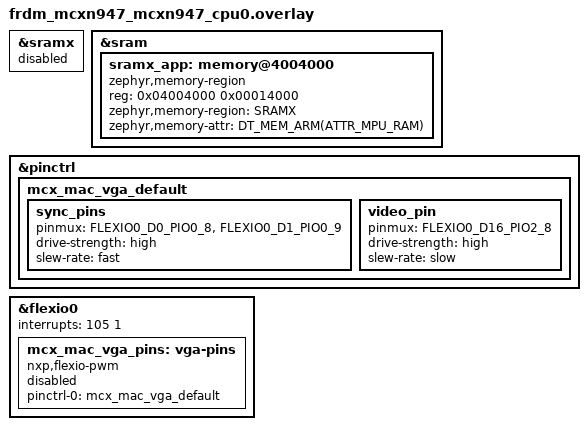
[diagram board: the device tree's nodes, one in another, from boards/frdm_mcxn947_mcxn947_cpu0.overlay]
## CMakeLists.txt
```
cmake_minimum_required(VERSION 3.20.0)

find_package(Zephyr REQUIRED HINTS $ENV{ZEPHYR_BASE})
project(mcx_mac)

# The public variant must neither link the legacy floppy driver nor embed
# private media. The post-build map/asset audit remains mandatory.
option(MCX_MAC_PUBLIC_RELEASE "Build an asset-free, release-audited image" ON)
if(MCX_MAC_PUBLIC_RELEASE AND
   (NOT CONFIG_MCX_MAC_UMAC_BOOT OR
    NOT CONFIG_MCX_MAC_UMAC_MEDIA_FROM_SLOT1 OR
    NOT CONFIG_MCX_MAC_INDEPENDENT_FLOPPY))
  message(FATAL_ERROR
    "Public uMac build requires boot + separate media slot + independent floppy. See RELEASE_STATUS.md")
endif()

if(MCX_MAC_PUBLIC_RELEASE AND CONFIG_MCX_MAC_USB_IMAGE_TRANSFER)
  message(FATAL_ERROR
    "Experimental USB transfer mode uses a test VID/PID and is not release-ready")
endif()

if(MCX_MAC_PUBLIC_RELEASE AND
   (CONFIG_MCX_MAC_UMAC_OPCODE_PROFILE OR CONFIG_MCX_MAC_UMAC_CYCLE_PROFILE))
  message(FATAL_ERROR "Diagnostic opcode profiling must not be included in a public build")
endif()

if(MCX_MAC_PUBLIC_RELEASE AND CONFIG_MCX_MAC_UMAC_MOVEM_MASK_ITER)
  message(FATAL_ERROR "Experimental MOVEM optimization is not release-validated")
endif()

if(MCX_MAC_PUBLIC_RELEASE AND CONFIG_MCX_MAC_UMAC_CPU_CONTEXT_RAMX)
  message(FATAL_ERROR "Experimental Musashi CPU context placement is not release-validated")
endif()

set(MCUX_CTIMER_DIR
  ${ZEPHYR_BASE}/../modules/hal/nxp/mcux/mcux-sdk-ng/drivers/ctimer)

target_include_directories(app PRIVATE
  src
  ${MCUX_CTIMER_DIR}
)

target_sources(app PRIVATE
  src/main.c
  src/emulator/m68k_bus.c
  src/emulator/m68k_bus_diag.c
  src/emulator/m68k_musashi_bus.c
  src/emulator/umac_memory.c
  src/emulator/umac_timing.c
  src/emulator/umac_video.c
  src/video/vga.c
  src/video/vga_flexio.c
  src/video/vga_smartdma.c
  src/video/vga_diag.c
  ${MCUX_CTIMER_DIR}/fsl_ctimer.c
)

if(CONFIG_MCX_MAC_EXTERNAL_FLASH_PROBE)
  target_sources(app PRIVATE src/emulator/umac_external_flash_probe.c)
endif()

if(CONFIG_MCX_MAC_EXTERNAL_FLASH_HDD)
  target_sources(app PRIVATE src/emulator/umac_flash_hdd.c)
endif()

if(CONFIG_MCX_MAC_EXTERNAL_FLASH_FAT_IMAGE)
  target_sources(app PRIVATE src/emulator/umac_fat_image.c)
endif()

if(CONFIG_MCX_MAC_USB_IMAGE_TRANSFER)
  target_sources(app PRIVATE src/usb/umac_usb_transfer.c)
endif()

if(CONFIG_MCX_MAC_SMARTDMA_DIRECT)
  if(CONFIG_MCX_MAC_SMARTDMA_GUEST_DESCRIPTOR)
    target_sources(app PRIVATE
      src/video/vga_smartdma_guest_ring.c
      src/video/vga_smartdma_guest_descriptors.c)
  else()
    target_sources(app PRIVATE src/video/vga_smartdma_ring.c)
  endif()
endif()

if(CONFIG_MCX_MAC_UMAC_CORE)
  if(NOT (CONFIG_MCX_MAC_UMAC_RAM_KIB EQUAL 128 OR
          CONFIG_MCX_MAC_UMAC_RAM_KIB EQUAL 192 OR
          CONFIG_MCX_MAC_UMAC_RAM_KIB EQUAL 208))
    message(FATAL_ERROR "Mac RAM must be 128, 192, or 208 KiB; the private ROM must match")
  endif()
  set(UMAC_DIR ${CMAKE_CURRENT_SOURCE_DIR}/external/umac)
  set(MUSASHI_DIR ${UMAC_DIR}/external/Musashi)
  set(UMAC_GEN_DIR ${CMAKE_CURRENT_BINARY_DIR}/umac_generated)
  set(UMAC_GENERATOR ${UMAC_GEN_DIR}/m68kmake)

  if(CONFIG_MCX_MAC_UMAC_RAM_KIB GREATER 192)
    # This board initializes only one EHCI host. Move the second instance's
    # untouched reserve, plus the CPU-only system heap, to free contiguous
    # main SRAM for the guest. Keep active USB DMA buffers in main SRAM.
    zephyr_code_relocate(
      FILES ${ZEPHYR_BASE}/../modules/hal/nxp/mcux/mcux-sdk-ng/middleware/usb/host/usb_host_ehci.c
      LOCATION SRAMX_BSS
      FILTER "^\\.bss\\.s_UsbHostEhci(FrameList2|Data2)$")
    zephyr_code_relocate(
      FILES ${ZEPHYR_BASE}/kernel/mempool.c
      LOCATION SRAMX_NOINIT
      FILTER "^\\.noinit\\..*kheap_buf__system_heap$")
  endif()

  if(NOT EXISTS ${MUSASHI_DIR}/m68kmake.c)
    message(FATAL_ERROR "uMac/Musashi not found; clone external/umac with --recursive")
  endif()

  find_program(UMAC_HOST_CC NAMES cc clang)
  if(NOT UMAC_HOST_CC)
    message(FATAL_ERROR "A host C compiler is required to generate Musashi opcodes")
  endif()

  set(UMAC_HOT_DECORATE_COMMAND)
  set(UMAC_HOT_DECORATE_DEPENDS)
  if(CONFIG_MCX_MAC_UMAC_HOT_OPS_RAM OR CONFIG_MCX_MAC_UMAC_HOT_OPS_RAMX)
    find_package(Python3 REQUIRED COMPONENTS Interpreter)
    set(UMAC_HOT_DECORATE_COMMAND
      COMMAND ${Python3_EXECUTABLE} ${UMAC_DIR}/tools/decorate_ops.py
              ${UMAC_GEN_DIR}/m68kops.c ${UMAC_DIR}/tools/fn_hot200.txt)
    set(UMAC_HOT_DECORATE_DEPENDS
      ${UMAC_DIR}/tools/decorate_ops.py ${UMAC_DIR}/tools/fn_hot200.txt)
  endif()

  set(UMAC_MOVEM_OPTIMIZE_COMMAND)
  set(UMAC_MOVEM_OPTIMIZE_DEPENDS)
  if(CONFIG_MCX_MAC_UMAC_MOVEM_MASK_ITER)
    find_package(Python3 REQUIRED COMPONENTS Interpreter)
    set(UMAC_MOVEM_OPTIMIZE_COMMAND
      COMMAND ${Python3_EXECUTABLE}
              ${CMAKE_CURRENT_SOURCE_DIR}/tools/optimize_m68kops_movem.py
              ${UMAC_GEN_DIR}/m68kops.c)
    set(UMAC_MOVEM_OPTIMIZE_DEPENDS
      ${CMAKE_CURRENT_SOURCE_DIR}/tools/optimize_m68kops_movem.py)
  endif()

  add_custom_command(
    OUTPUT ${UMAC_GEN_DIR}/m68kops.c ${UMAC_GEN_DIR}/m68kops.h
    COMMAND ${CMAKE_COMMAND} -E make_directory ${UMAC_GEN_DIR}
    COMMAND ${UMAC_HOST_CC} -O2 ${MUSASHI_DIR}/m68kmake.c -o ${UMAC_GENERATOR}
    COMMAND ${UMAC_GENERATOR} ${UMAC_GEN_DIR} ${MUSASHI_DIR}/m68k_in.c
    ${UMAC_HOT_DECORATE_COMMAND}
    ${UMAC_MOVEM_OPTIMIZE_COMMAND}
    DEPENDS ${MUSASHI_DIR}/m68kmake.c ${MUSASHI_DIR}/m68k_in.c
            ${UMAC_HOT_DECORATE_DEPENDS} ${UMAC_MOVEM_OPTIMIZE_DEPENDS}
    VERBATIM
  )

  target_include_directories(app PRIVATE
    ${UMAC_DIR}/include
    ${MUSASHI_DIR}
    ${UMAC_GEN_DIR}
  )
  target_compile_definitions(app PRIVATE
    UMAC_MEMSIZE=${CONFIG_MCX_MAC_UMAC_RAM_KIB}
    # Keep the original 30-step mouse backlog. Shorter 68000 slices let
    # the emulated mouse issue more quadrature steps per wall-clock second.
    MCX_MAC_GUEST_LOOP_MS=1
    MCX_MAC_MOUSE_SUBSTEPS=2
    MCX_MAC_USB_MOUSE_RATE_MAP=1
    DISP_WIDTH=512
    DISP_HEIGHT=342
    MUSASHI_CNF=\"${CMAKE_CURRENT_SOURCE_DIR}/src/emulator/mcx_m68kconf.h\"
  )
  set(UMAC_M68KCPU_SOURCE ${MUSASHI_DIR}/m68kcpu.c)
  if(CONFIG_MCX_MAC_UMAC_OPCODE_PROFILE OR CONFIG_MCX_MAC_UMAC_CYCLE_PROFILE)
    find_package(Python3 REQUIRED COMPONENTS Interpreter)
    set(UMAC_M68KCPU_SOURCE ${UMAC_GEN_DIR}/m68kcpu_profile.c)
    if(CONFIG_MCX_MAC_UMAC_CYCLE_PROFILE)
      set(UMAC_PROFILE_KIND cycles)
      target_sources(app PRIVATE src/emulator/mcx_cycle_profile.c)
    else()
      set(UMAC_PROFILE_KIND count)
      target_sources(app PRIVATE src/emulator/mcx_opcode_profile.c)
    endif()
    add_custom_command(
      OUTPUT ${UMAC_M68KCPU_SOURCE}
      COMMAND ${CMAKE_COMMAND} -E make_directory ${UMAC_GEN_DIR}
      COMMAND ${Python3_EXECUTABLE}
              ${CMAKE_CURRENT_SOURCE_DIR}/tools/instrument_m68kcpu.py
              ${MUSASHI_DIR}/m68kcpu.c ${UMAC_M68KCPU_SOURCE}
              ${UMAC_PROFILE_KIND}
      DEPENDS ${MUSASHI_DIR}/m68kcpu.c
              ${CMAKE_CURRENT_SOURCE_DIR}/tools/instrument_m68kcpu.py
      VERBATIM
    )
  endif()
  if(CONFIG_MCX_MAC_UMAC_CPU_CONTEXT_RAMX)
    find_package(Python3 REQUIRED COMPONENTS Interpreter)
    set(UMAC_M68KCPU_CONTEXT_INPUT ${UMAC_M68KCPU_SOURCE})
    set(UMAC_M68KCPU_SOURCE ${UMAC_GEN_DIR}/m68kcpu_context_ramx.c)
    add_custom_command(
      OUTPUT ${UMAC_M68KCPU_SOURCE}
      COMMAND ${Python3_EXECUTABLE}
              ${CMAKE_CURRENT_SOURCE_DIR}/tools/place_m68kcpu_context_ramx.py
              ${UMAC_M68KCPU_CONTEXT_INPUT} ${UMAC_M68KCPU_SOURCE}
      DEPENDS ${UMAC_M68KCPU_CONTEXT_INPUT}
              ${CMAKE_CURRENT_SOURCE_DIR}/tools/place_m68kcpu_context_ramx.py
      VERBATIM
    )
  endif()
  target_sources(app PRIVATE
    src/emulator/umac_block_backend.c
    src/emulator/umac_media_package.c
    ${UMAC_DIR}/src/main.c
    ${UMAC_DIR}/src/via.c
    ${UMAC_DIR}/src/scc.c
    ${UMAC_DIR}/src/rtc.c
    ${UMAC_M68KCPU_SOURCE}
    ${MUSASHI_DIR}/m68kdasm.c
    ${UMAC_GEN_DIR}/m68kops.c
  )
  if(CONFIG_MCX_MAC_UMAC_HOT_OPS_RAMX)
    zephyr_code_relocate(
      FILES ${MUSASHI_DIR}/m68kcpu.c ${UMAC_GEN_DIR}/m68kops.c
      LOCATION SRAMXHOT
      FILTER "^\\.text\\.mcx_hot$")
  endif()
  if(CONFIG_MCX_MAC_UMAC_CPU_O2)
    set_source_files_properties(
      ${UMAC_M68KCPU_SOURCE}
      ${UMAC_GEN_DIR}/m68kops.c
      PROPERTIES COMPILE_OPTIONS "-O2")
  endif()
  target_sources(app PRIVATE src/emulator/umac_floppy.c)
  if(CONFIG_MCX_MAC_UMAC_SMOKE)
    target_sources(app PRIVATE src/emulator/umac_smoke.c)
  endif()
  if(CONFIG_MCX_MAC_UMAC_BOOT)
    target_sources(app PRIVATE
      src/emulator/umac_disk_overlay.c
      src/emulator/umac_serial_input.c)
    target_sources(app PRIVATE src/emulator/umac_media_slot_boot.c)
    if(CONFIG_MCX_MAC_USB_MOUSE)
      target_sources(app PRIVATE src/emulator/umac_usb_hid.c)
      target_include_directories(app PRIVATE ${ZEPHYR_BASE}/subsys/usb/host)
    endif()
  endif()
endif()
```

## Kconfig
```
mainmenu "mcx_mac"

source "Kconfig.zephyr"

config MCX_MAC_FLEXIO
	bool
	default y
	select MCUX_FLEXIO
	help
	  Build the MCX-N FlexIO timing backend. The application attaches its
	  timer resource to Zephyr's shared NXP FlexIO controller.

config MCX_MAC_EDMA_LINKED
	bool "Use experimental eDMA TCD line linking"
	default n
	depends on MCX_MAC_FLEXIO
	help
	  Use MCUXpresso eDMA TCDs linked at each 512-pixel line boundary.
	  The linked diagnostic path is disabled by default until hardware
	  measurements confirm its FlexIO request gating.

config MCX_MAC_SOLID_VIDEO_DIAG
	bool "Drive a solid VIDEO rectangle without DMA"
	default n
	depends on MCX_MAC_FLEXIO
	help
	  Diagnostic mode which bypasses eDMA and the pixel serializer. The
	  HSYNC line interrupt drives a solid green rectangle directly, allowing
	  the analog/sync path to be separated from packed framebuffer scanout.

config MCX_MAC_HARDWARE_VIDEO_DIAG
	bool "Generate a periodic VIDEO window entirely in FlexIO"
	default n
	depends on MCX_MAC_FLEXIO
	help
	  Diagnostic mode which bypasses eDMA, the pixel serializer, and the
	  per-scanline CPU interrupt. A second FlexIO timer produces the VIDEO
	  window from the same clock as HSYNC so line-to-line timing cannot jitter.

config MCX_MAC_CONTINUOUS_RASTER
	bool "Stream a complete VGA raster without per-line CPU starts"
	default n
	depends on MCX_MAC_FLEXIO
	help
	  Expand the monochrome framebuffer into a packed 800 by 525 raster and
	  stream it continuously with one cyclic eDMA TCD. HSYNC and pixels share
	  the FlexIO clock and no scanline interrupt participates in video timing.

config MCX_MAC_SMARTDMA_DIRECT
	bool "Experimental SmartDMA one-frame FlexIO scanout"
	default n
	depends on MCX_MAC_CONTINUOUS_RASTER
	help
	  Replace the two-frame eDMA raster with a single 800x525 frame streamed
	  by a custom SmartDMA program. This is an experimental video path; leave
	  disabled in the known-working public build until display verification.

config MCX_MAC_SMARTDMA_RAW_PIXEL_ALIAS
	bool "Experimental raw raster through FlexIO bit-byte-swap alias"
	default n
	depends on MCX_MAC_SMARTDMA_DIRECT
	help
	  Keep the existing full-frame SmartDMA source but store raw Macintosh
	  pixel bytes in it. Direct SmartDMA writes to FlexIO SHIFTBUFBBS reverse
	  each byte's bits in hardware. This isolates alias behavior before a
	  direct guest-memory reader replaces the full-frame raster.

config MCX_MAC_SMARTDMA_GUEST_DESCRIPTOR
	bool "Experimental direct guest-framebuffer SmartDMA scanout"
	default n
	depends on MCX_MAC_SMARTDMA_DIRECT && MCX_MAC_SMARTDMA_RAW_PIXEL_ALIAS
	depends on !MCX_MAC_VIDEO_RAM_BANK
	help
	  Store the VGA scan schedule in Flash and have SmartDMA fetch packed
	  pixels directly from the Macintosh framebuffer. This removes the
	  52,500-byte expanded raster but is still an experimental video path.

config MCX_MAC_VIDEO_RAM_BANK
	bool "Place the SmartDMA raster wholly in the final 64 KiB main-RAM bank"
	default n
	depends on MCX_MAC_SMARTDMA_DIRECT
	help
	  Requires boards/smartdma_video_bank.overlay. The overlay shrinks the
	  normal application RAM to 256 KiB and reserves the final 64 KiB bank
	  for the 52,500-byte raster so SmartDMA reads cannot cross a RAM bank.

config MCX_MAC_FRAMEBUFFER_SRAMX
	bool "Place the CPU-side Macintosh framebuffer in SRAMX"
	default n
	depends on MCX_MAC_CONTINUOUS_RASTER
	help
	  Experimental RAM-placement option. Move the 512x342 monochrome
	  conversion framebuffer (21,888 bytes) from the nearly full main RAM
	  into SRAMX. Continuous eDMA still reads its existing two-frame raster
	  from main RAM; timing and transfer descriptors do not change.

config MCX_MAC_ANIMATED_TEST
	bool "Animate the checkerboard through vertical-blank commits"
	default n
	depends on MCX_MAC_CONTINUOUS_RASTER
	help
	  Shift the checkerboard by eight pixels twice per second. This verifies
	  that framebuffer changes can be committed during vertical blank while
	  the cyclic scanout DMA remains uninterrupted.

config MCX_MAC_M68K_BUS_DIAG
	bool "Run the 68000 memory-bus and CPU-callback self-test"
	default y
	help
	  Verify the 24-bit address mask, big-endian accesses, reset ROM overlay,
	  RAM writes below the overlay, unmapped-access diagnostics, and the
	  Musashi-compatible memory callback adapter. No CPU core runs yet.

config MCX_MAC_UMAC_CORE
	bool "Compile the upstream uMac/Musashi 128K core"
	default n
	help
	  Compile the upstream emulator from external/umac with generated
	  Musashi opcode sources. This option alone does not run guest code;
	  a user-provided, patched ROM and disc image are still required.

config MCX_MAC_EXTERNAL_FLASH_PROBE
	bool "Read-only probe of onboard FlexSPI NOR for future disk backend"
	default n
	depends on FLASH
	help
	  Check the onboard external NOR device, JEDEC ID, capacity, and whether
	  its first and last erase sectors are blank. This option never erases or
	  writes external Flash and does not change the guest disk backend.

config MCX_MAC_EXTERNAL_FLASH_WRITE_TEST
	bool "Test and restore one confirmed-blank external Flash sector"
	default n
	depends on MCX_MAC_EXTERNAL_FLASH_PROBE
	help
	  On a matching W25Q64 only, require the final 4 KiB sector to be all
	  0xff, program a 256-byte pattern, verify it, erase the sector, and
	  verify it is blank again. Never run on a nonblank sector. This is an
	  opt-in development test; it does not enable persistent guest writes.

config MCX_MAC_UMAC_FIXED_DISK_ROM
	bool "Use the experimental two-drive private Macintosh ROM"
	default n
	help
	  Require the private ROM variant with a second, fixed-disk Device
	  Manager entry. This does not require or access external Flash by
	  itself and is useful for isolating Macintosh boot behavior.

config MCX_MAC_EXTERNAL_FLASH_HDD
	bool "Build external Flash Macintosh fixed-disk backend (experimental)"
	default n
	depends on FLASH
	select MCX_MAC_UMAC_FIXED_DISK_ROM
	help
	  Build the fixed-disk block backend in the onboard W25Q64. The first
	  and last 64 KiB erase sectors are reserved, with one additional 4 KiB
	  header, yielding a 16120-sector device as Mac drive 8. It never
	  automatically initializes blank Flash. The
	  Mac can then initialize it as a normal volume. Writes currently use
	  non-atomic erase-block read/modify/write and are not power-loss safe.

config MCX_MAC_EXTERNAL_FLASH_FAT_IMAGE
	bool "Use an existing raw HFS/MFS image file on the external FAT volume"
	default n
	depends on FLASH && DISK_DRIVER_FLASH && FAT_FILESYSTEM_ELM
	depends on !MCX_MAC_EXTERNAL_FLASH_HDD
	select MCX_MAC_UMAC_FIXED_DISK_ROM
	help
	  Open /NAND:/umac0.img as Mac drive 8. HFS is writable; MFS is
	  read-only pending fixed-disk compatibility testing. The volume and file
	  must already exist; firmware does not format the volume or create/truncate
	  the image.
	  Do not expose the FAT volume to a USB host while the Mac is using it.

config MCX_MAC_USB_IMAGE_TRANSFER
	bool "Experimental SW2-selected USB image transfer mode"
	default n
	depends on MCX_MAC_EXTERNAL_FLASH_FAT_IMAGE && USB_DEVICE_STACK_NEXT
	depends on USBD_MSC_CLASS && USB_HOST_STACK && GPIO
	help
	  Compile both USB1 roles. Holding user SW2 at startup starts the USB
	  device/MSC mode instead of the Macintosh. This is a private build probe
	  with a non-production VID/PID, not a release feature.

config MCX_MAC_EXTERNAL_FLASH_HDD_FORMAT_BLANK
	bool "Explicitly initialize a completely blank external Flash HDD area"
	default n
	depends on MCX_MAC_EXTERNAL_FLASH_HDD
	help
	  Development-only, one-time operation. Formatting scans the disk area and
	  refuses to modify it if any byte is not erased. This does not create an
	  HFS volume. Never enable in a normal release image.

config MCX_MAC_EXTERNAL_FLASH_HDD_SKIP_MEDIA
	bool "Keep fixed-disk ROM driver but do not access external media"
	default n
	depends on MCX_MAC_EXTERNAL_FLASH_HDD
	depends on !MCX_MAC_EXTERNAL_FLASH_HDD_FORMAT_BLANK
	help
	  Diagnostic only: boot with the two-drive ROM patch but leave drive 8
	  unattached. This isolates guest driver registration from external NOR
	  reads and writes. The System floppy remains available.

config MCX_MAC_UMAC_SMOKE
	bool "Run a synthetic uMac/Musashi CPU smoke test"
	default n
	depends on MCX_MAC_UMAC_CORE
	help
	  Execute a short 68000 branch loop from a project-owned synthetic ROM.
	  This is only a CPU/link test, not Macintosh boot or video output.

config MCX_MAC_UMAC_BOOT
	bool "Boot uMac with locally supplied ROM and disk"
	default n
	depends on MCX_MAC_UMAC_CORE && MCX_MAC_CONTINUOUS_RASTER
	help
	  Embed user-supplied ROM and disk images into a local firmware build.
	  Neither image is copied into the source tree. Do not distribute the
	  resulting firmware without appropriate rights to those images.

config MCX_MAC_UMAC_PERF_DIAG
	bool "Measure uMac loop and video-service CPU time"
	default n
	depends on MCX_MAC_UMAC_BOOT
	help
	  Record cycle counts for the guest loop, video copy, raster service and
	  main-thread sleep. Print aggregate timing every five seconds. Keep this
	  disabled in the normal build to avoid adding timing probes to hot paths.

config MCX_MAC_UMAC_INSTR_COUNT
	bool "Count executed guest 68000 instructions for a diagnostic build"
	default n
	depends on MCX_MAC_UMAC_BOOT
	help
	  Increment a counter for each 68000 instruction and report kIPS every
	  five seconds. The hook adds overhead, so compare two builds made with
	  this same option rather than treating its rate as an uninstrumented MIPS.

config MCX_MAC_UMAC_RAM_KIB
	int "Macintosh guest RAM in KiB"
	default 128
	range 128 208
	depends on MCX_MAC_UMAC_CORE
	help
	  The 128 KiB normal build is unchanged. Larger values need the matching
	  private ROM memory-top patch, and enough contiguous CPU0 RAM. The
	  192 KiB variant moves the CPU-side framebuffer into SRAMX. The 208 KiB
	  variant also moves unused USB reserve data and the system heap to SRAMX.
	  Only 128, 192, and 208 KiB have matching private ROM patches.

config MCX_MAC_UMAC_OPCODE_PROFILE
	bool "Sample executed Musashi opcode handlers for a diagnostic build"
	default n
	depends on MCX_MAC_UMAC_BOOT && !MCX_MAC_UMAC_HOT_OPS_RAM && !MCX_MAC_UMAC_HOT_OPS_RAMX
	help
	  Sample the actual opcode-handler dispatch on CPU0, storing counts in
	  spare RAMX. The generated Musashi source is instrumented only for this
	  diagnostic build; the vendored submodule and release image are untouched.

config MCX_MAC_UMAC_CYCLE_PROFILE
	bool "Sample actual CPU cycles spent in Musashi opcode handlers"
	default n
	depends on MCX_MAC_UMAC_BOOT && !MCX_MAC_UMAC_HOT_OPS_RAM && !MCX_MAC_UMAC_HOT_OPS_RAMX && !MCX_MAC_UMAC_OPCODE_PROFILE
	help
	  Time one of approximately every 64 dispatched guest instructions and
	  rank handlers by accumulated CPU cycles, not just execution frequency.
	  This diagnostic has measurement overhead and may include interrupt time.
	  The sample table occupies 16 KiB of main RAM; do not enable in release.

config MCX_MAC_UMAC_MOVEM_MASK_ITER
	bool "Experiment with set-bit iteration in two hot MOVEM handlers"
	default n
	depends on MCX_MAC_UMAC_BOOT && !MCX_MAC_UMAC_HOT_OPS_RAM && !MCX_MAC_UMAC_HOT_OPS_RAMX
	help
	  Rewrite only the generated copies of MOVEM.L register-to-memory
	  predecrement and memory-to-register postincrement handlers. Iterate
	  selected register bits instead of testing all 16 slots. This is an
	  experimental A/B optimization; leave disabled in a release build.

config MCX_MAC_UMAC_CPU_CONTEXT_RAMX
	bool "Experiment with Musashi CPU register state in app SRAMX"
	default n
	depends on MCX_MAC_UMAC_BOOT && !MCX_MAC_UMAC_HOT_OPS_RAMX
	help
	  Relocate only the 536-byte Musashi CPU state to the existing app SRAMX
	  data bank. The guest RAM, opcode dispatch table and firmware stay in
	  their original locations. This is an experimental A/B option.

config MCX_MAC_UMAC_HOT_OPS_RAM
	bool "Experiment with uMac's hot 200 opcode handlers in RAM"
	default n
	depends on MCX_MAC_UMAC_BOOT && ARCH_HAS_RAMFUNC_SUPPORT
	help
	  Decorate uMac's profiled 200 opcode handlers and the Musashi dispatcher
	  for Zephyr's startup-copied executable .ramfunc section. This first
	  experiment uses ordinary CPU0 RAM, not RAMX, because the existing RAMX
	  device-tree region is data-only under the MPU. Leave off in release
	  builds until speed, free RAM and video stability are measured.

config MCX_MAC_UMAC_HOT_OPS_RAMX
	bool "Experiment with uMac's hot 200 opcode handlers in isolated RAMX"
	default n
	depends on MCX_MAC_UMAC_BOOT && CODE_DATA_RELOCATION && !MCX_MAC_UMAC_HOT_OPS_RAM
	help
	  Relocate the 200 profiled handlers and the Musashi dispatcher to a
	  dedicated executable RAMX bank. The disk overlay remains in a separate
	  32 KiB RAMX region. This is an experimental diagnostic build only.

config MCX_MAC_USB_THREAD_PROFILE
	bool "Measure USB host thread CPU time"
	default n
	depends on MCX_MAC_USB_MOUSE && THREAD_RUNTIME_STATS && THREAD_MONITOR && THREAD_NAME
	help
	  Print five-second runtime deltas for the Zephyr USB host, bus and
	  controller threads. This is a diagnostic build option only: scheduler
	  runtime accounting has overhead and does not isolate USB interrupt time.

config MCX_MAC_UMAC_FAST_SCHED
	bool "Experiment with 100 us guest scheduling intervals"
	default n
	depends on MCX_MAC_UMAC_BOOT
	help
	  Replace the main loop's unconditional 1 ms sleep with a one-tick
	  (100 us at the present 10 kHz kernel tick) sleep while the guest runs.
	  USB host threads remain preemptive. Compare timing, input and VGA
	  stability before enabling this in the normal build.

config MCX_MAC_UMAC_WORD_VIDEO
	bool "Experiment with word-at-a-time framebuffer comparison"
	default n
	depends on MCX_MAC_UMAC_BOOT
	help
	  Compare and copy aligned framebuffer data as 32-bit words, falling back
	  to the bytewise library routines for unaligned inputs. EXP-72 reduced
	  video CPU time but made visible display artifacts worse, so leave this
	  disabled while investigating memory-bus contention.

config MCX_MAC_UMAC_VIDEO_DIRTY_TRACK
	bool "Experiment with guest framebuffer write tracking"
	default n
	depends on MCX_MAC_UMAC_BOOT
	help
	  Mark the guest display dirty on uMac CPU and floppy writes to its RAM
	  range. Skip the full 21,888-byte comparison on clean VSYNCs. This is
	  experimental until live Finder, mouse and window redraws are checked.

config MCX_MAC_UMAC_CPU_O2
	bool "Experiment with -O2 for the Musashi 68000 core"
	default n
	depends on MCX_MAC_UMAC_BOOT
	help
	  Compile only the Musashi CPU dispatcher and generated opcode handlers
	  with -O2 instead of Zephyr's default -Os. This tests whether guest CPU
	  throughput can improve without changing raster memory traffic.

config MCX_MAC_UMAC_YIELD_SCHED
	bool "Experiment with zero fixed sleep while the guest runs"
	default n
	depends on MCX_MAC_UMAC_BOOT
	help
	  Yield the main thread instead of waiting for a kernel timer tick.
	  This can improve guest throughput but may keep CPU0 fully busy.
	  Verify USB latency and video stability before adopting it.

config MCX_MAC_UMAC_MEDIA_FROM_SLOT1
	bool "Read separately installed private media from image-1 flash slot"
	default n
	depends on MCX_MAC_UMAC_BOOT
	help
	  Read a checksummed ROM/disk package already installed in the board's
	  image-1 partition. This does not write flash. The image-1 partition
	  cannot simultaneously serve as an MCUboot update slot. The package
	  must be created and installed separately by the device owner.

config MCX_MAC_INDEPENDENT_FLOPPY
	bool "Use project-owned Device Manager floppy implementation"
	default n
	depends on MCX_MAC_UMAC_CORE
	help
	  Experimental replacement for uMac's GPLv2-derived disc.c. Requires
	  a separately patched ROM with the matching project-owned 68000 stub.

config MCX_MAC_USB_MOUSE
	bool "Connect generic USB Boot keyboard and mouse input to uMac"
	default n
	depends on MCX_MAC_UMAC_BOOT && USB_HOST_STACK
	help
	  Discover USB HID Boot keyboard and mouse interfaces on J11 without
	  depending on a particular vendor, product, interface number, or endpoint.
	  Composite wireless receivers exposing both Boot interfaces are supported.
```

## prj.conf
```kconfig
CONFIG_CONSOLE=y
CONFIG_UART_CONSOLE=y
CONFIG_SERIAL=y
CONFIG_PRINTK=y

CONFIG_PINCTRL=y
CONFIG_CLOCK_CONTROL=y
CONFIG_DMA=y

CONFIG_MAIN_STACK_SIZE=2048
CONFIG_ASSERT=y
CONFIG_MCX_MAC_EDMA_LINKED=n
CONFIG_MCX_MAC_SOLID_VIDEO_DIAG=n
CONFIG_MCX_MAC_HARDWARE_VIDEO_DIAG=n
CONFIG_MCX_MAC_CONTINUOUS_RASTER=y
CONFIG_MCX_MAC_ANIMATED_TEST=n
CONFIG_MCX_MAC_M68K_BUS_DIAG=y
CONFIG_MCX_MAC_UMAC_CORE=y
CONFIG_MCX_MAC_UMAC_SMOKE=y
CONFIG_DMA_TCD_QUEUE_SIZE=2
```

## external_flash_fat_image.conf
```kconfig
# Existing host-readable FAT volume holding one raw HFS or MFS Mac image.
# Never autoformat the current W25Q64 raw-HFS layout.
CONFIG_FLASH=y
CONFIG_FLASH_JESD216_API=y
CONFIG_FLASH_MAP=y
CONFIG_DISK_DRIVER_FLASH=y
CONFIG_FILE_SYSTEM=y
CONFIG_FAT_FILESYSTEM_ELM=y
CONFIG_FS_FATFS_MOUNT_MKFS=n
CONFIG_MCX_MAC_EXTERNAL_FLASH_FAT_IMAGE=y
```

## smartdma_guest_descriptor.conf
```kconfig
CONFIG_MCX_MAC_SMARTDMA_DIRECT=y
CONFIG_MCX_MAC_SMARTDMA_RAW_PIXEL_ALIAS=y
CONFIG_MCX_MAC_SMARTDMA_GUEST_DESCRIPTOR=y
CONFIG_MCX_MAC_FRAMEBUFFER_SRAMX=n
CONFIG_MCX_MAC_VIDEO_RAM_BANK=n
```

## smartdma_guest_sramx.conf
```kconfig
CONFIG_MCX_MAC_FRAMEBUFFER_SRAMX=y
```

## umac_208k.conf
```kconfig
# Experimental 208 KiB Macintosh guest RAM, with main-SRAM reserves in RAMX.
CONFIG_MCX_MAC_UMAC_RAM_KIB=208
CONFIG_MCX_MAC_FRAMEBUFFER_SRAMX=y
CONFIG_CODE_DATA_RELOCATION=y
```

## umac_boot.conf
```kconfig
CONFIG_MCX_MAC_UMAC_BOOT=y
CONFIG_MCX_MAC_UMAC_SMOKE=n
CONFIG_MAIN_STACK_SIZE=8192
CONFIG_BUILD_OUTPUT_HEX=y
```

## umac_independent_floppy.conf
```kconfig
CONFIG_MCX_MAC_INDEPENDENT_FLOPPY=y
```

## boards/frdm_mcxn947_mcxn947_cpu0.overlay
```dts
/*
 * Phase 2 VGA sync and packed monochrome VIDEO routing.
 *
 * The selections below are deliberately isolated in this overlay so a
 * carrier board can move the signals without changing the driver:
 *   PIO0_8 / FLEXIO0_D0 -> HSYNC
 *   PIO0_9 / FLEXIO0_D1 -> VSYNC
 *   PIO2_8 / FLEXIO0_D16 -> monochrome VIDEO (Phase 2, J8 pin 13)
 *
 * These mux choices exist in MCXN947VDF-pinctrl.h and are also used by the
 * FRDM-MCXN947 FlexIO LCD pin group. Only D16 is used for video.
 */

#include <nxp/mcx/MCXN947VDF-pinctrl.h>

/* 0x04000000 and 0x14000000 are aliases of the same RAMX bytes. SmartDMA
 * firmware is installed at 0x04000000, so the app's SRAMX linker section
 * must not begin at the default 0x14000000. Reserve the first 16 KiB for
 * SmartDMA code and use the remaining 80 KiB for application data.
 */
&sramx {
	/delete-property/ zephyr,memory-region;
	status = "disabled";
};

&sram {
	sramx_app: memory@4004000 {
		compatible = "zephyr,memory-region", "mmio-sram";
		reg = <0x04004000 0x00014000>;
		zephyr,memory-region = "SRAMX";
		zephyr,memory-attr = <DT_MEM_ARM(ATTR_MPU_RAM)>;
	};
};

&pinctrl {
	mcx_mac_vga_default: mcx_mac_vga_default {
		sync_pins {
			pinmux = <FLEXIO0_D0_PIO0_8>,
				 <FLEXIO0_D1_PIO0_9>;
			drive-strength = "high";
			slew-rate = "fast";
		};

		video_pin {
			pinmux = <FLEXIO0_D16_PIO2_8>;
			/* A 25 MHz monochrome output on loose jumper wiring does not
			 * need the fastest edge. Keep enough drive for the VGA divider
			 * while reducing reflections and overshoot. */
			drive-strength = "high";
			slew-rate = "slow";
		};
	};
};

&flexio0 {
	status = "okay";
	/* Let the eDMA completion IRQ (priority 0) preempt the HSYNC handler's
	 * short pixel-positioning delay instead of being held until the next line.
	 */
	interrupts = <105 1>;

	/*
	 * A disabled child gives the application a standard pinctrl-device node
	 * without instantiating Zephyr's PWM driver or consuming a timer.
	 */
	mcx_mac_vga_pins: vga-pins {
		compatible = "nxp,flexio-pwm";
		status = "disabled";
		#pwm-cells = <3>;
		pinctrl-0 = <&mcx_mac_vga_default>;
		pinctrl-names = "default";
	};
};
```

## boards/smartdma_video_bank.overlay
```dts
/* SPDX-License-Identifier: MIT */
/* Experimental: carve the final 64 KiB bank out of the CPU0's 320 KiB RAM.
 * The CPU/USB allocations remain in the first 256 KiB, while the one-frame
 * SmartDMA video source occupies its own physical bank at 0x30040000.
 */
#include <zephyr/dt-bindings/memory-attr/memory-attr-arm.h>

&sram0 {
	reg = <0x20000000 0x00040000>;
};

&sram {
	video_ram_bank: memory@20040000 {
		compatible = "zephyr,memory-region", "mmio-sram";
		reg = <0x20040000 0x00010000>;
		zephyr,memory-region = "VIDEO_RAM";
		zephyr,memory-attr = <DT_MEM_ARM(ATTR_MPU_RAM)>;
	};
};
```

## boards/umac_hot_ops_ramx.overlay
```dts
/* SPDX-License-Identifier: MIT */
/* SmartDMA firmware: 0x14000000..0x14003fff (16 KiB).
 * Volatile disk overlay: 0x14004000..0x1400bfff (32 KiB).
 * Executable hot 68000 code: 0x1400c000..0x14017fff (48 KiB).
 */
#include <zephyr/dt-bindings/memory-attr/memory-attr-arm.h>

&sramx_app {
	reg = <0x04004000 0x00008000>;
};

&sram {
	ramx_hot: memory@400c000 {
		compatible = "zephyr,memory-region", "mmio-sram";
		reg = <0x0400c000 0x0000c000>;
		zephyr,memory-region = "SRAMXHOT";
		zephyr,memory-region-flags = "rx";
		zephyr,memory-attr = <DT_MEM_ARM(ATTR_MPU_FLASH)>;
	};
};
```

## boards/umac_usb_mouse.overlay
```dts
zephyr_uhc0: &usb1 {
	compatible = "nxp,uhc-ehci";
	status = "okay";
	phy-handle = <&usbphy1>;
	/delete-property/ num-bidir-endpoints;
};
```

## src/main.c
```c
/* SPDX-License-Identifier: MIT */
#include <zephyr/kernel.h>
#include <zephyr/sys/printk.h>
#if defined(CONFIG_MCX_MAC_UMAC_OPCODE_PROFILE) || defined(CONFIG_MCX_MAC_UMAC_CYCLE_PROFILE)
#include <fsl_common.h>
#endif
#if defined(CONFIG_MCX_MAC_UMAC_OPCODE_PROFILE)
#include "emulator/mcx_opcode_profile.h"
#endif
#if defined(CONFIG_MCX_MAC_UMAC_CYCLE_PROFILE)
#include "emulator/mcx_cycle_profile.h"
#endif
#if defined(CONFIG_MCX_MAC_USB_THREAD_PROFILE)
#include <string.h>
#endif

#include "emulator/m68k_bus.h"
#include "emulator/umac_memory.h"
#include "emulator/umac_timing.h"
#if defined(CONFIG_MCX_MAC_USB_IMAGE_TRANSFER)
#include "usb/umac_usb_transfer.h"
#endif
#if defined(CONFIG_MCX_MAC_EXTERNAL_FLASH_PROBE)
#include "emulator/umac_external_flash_probe.h"
#endif
#if defined(CONFIG_MCX_MAC_UMAC_BOOT)
#include "emulator/umac_boot.h"
#include "emulator/umac_disk_overlay.h"
#include "emulator/umac_serial_input.h"
#include "emulator/umac_video.h"
#if defined(CONFIG_MCX_MAC_USB_MOUSE)
#include "emulator/umac_usb_mouse.h"
#endif
#include <m68k.h>
#include <umac.h>
#endif
#if defined(CONFIG_MCX_MAC_UMAC_SMOKE)
#include "emulator/umac_smoke.h"
#endif
#include "video/vga.h"

#ifndef MCX_MAC_GUEST_LOOP_MS
#define MCX_MAC_GUEST_LOOP_MS 5U
#endif

#if defined(CONFIG_MCX_MAC_UMAC_INSTR_COUNT)
/* Diagnostic only: the Musashi instruction hook increments this on CPU0. */
volatile unsigned int mcx_mac_guest_instructions;
#endif

#if defined(CONFIG_MCX_MAC_USB_THREAD_PROFILE)
struct usb_thread_snapshot {
	k_tid_t threads[32];
	size_t count;
};

static void collect_usb_thread(const struct k_thread *thread, void *user_data)
{
	struct usb_thread_snapshot *snapshot = user_data;

	if (snapshot->count < ARRAY_SIZE(snapshot->threads)) {
		snapshot->threads[snapshot->count++] = (k_tid_t)thread;
	}
}

static void report_usb_thread_cycles(uint32_t interval_ms)
{
	static const char *const names[] = {
		"uhc_mcux_ehci", "usbh", "usbh_bus"
	};
	static uint64_t previous[ARRAY_SIZE(names)];
	static bool seen[ARRAY_SIZE(names)];
	struct usb_thread_snapshot snapshot = { 0 };
	uint32_t thread_ms[ARRAY_SIZE(names)] = { 0 };
	uint32_t found = 0U;
	uint64_t total_cycles = 0U;
	uint32_t cycles_per_ms = sys_clock_hw_cycles_per_sec() / 1000U;

	/* Collect under the thread-list lock; query stats after it is released. */
	k_thread_foreach(collect_usb_thread, &snapshot);
	for (size_t i = 0U; i < snapshot.count; i++) {
		const char *name = k_thread_name_get(snapshot.threads[i]);
		k_thread_runtime_stats_t stats;

		if (name == NULL || k_thread_runtime_stats_get(snapshot.threads[i], &stats) != 0) {
			continue;
		}
		for (size_t j = 0U; j < ARRAY_SIZE(names); j++) {
			if (strcmp(name, names[j]) != 0) {
				continue;
			}
			uint64_t delta = seen[j] ? stats.execution_cycles - previous[j] : 0U;

			previous[j] = stats.execution_cycles;
			seen[j] = true;
			found |= BIT(j);
			thread_ms[j] = (uint32_t)(delta / cycles_per_ms);
			total_cycles += delta;
			break;
		}
	}
	printk("DIAG USB CPU interval_ms=%u found=%x ehci_ms=%u host_ms=%u "
	       "bus_ms=%u total_ms=%u pct_x10=%u%s\n",
	       interval_ms, found, thread_ms[0], thread_ms[1], thread_ms[2],
	       (uint32_t)(total_cycles / cycles_per_ms),
	       interval_ms == 0U ? 0U :
	       (uint32_t)(total_cycles * 1000000U /
			  ((uint64_t)interval_ms * sys_clock_hw_cycles_per_sec())),
	       (found == BIT_MASK(ARRAY_SIZE(names))) ? "" : " (incomplete)");
}
#endif

int main(void)
{
	struct vga_timing_report report;
	struct vga_smartdma_stats stats;
	struct umac_timing timing = { 0 };
	uint32_t umac_vsync_ticks = 0U;
	uint32_t umac_second_ticks = 0U;
	uint32_t next_report_ms;
#if defined(CONFIG_MCX_MAC_UMAC_BOOT)
	uint32_t guest_loops = 0U;
	uint32_t next_guest_ms = 0U;
	bool guest_active = false;
#endif
#if defined(CONFIG_MCX_MAC_UMAC_PERF_DIAG)
	uint64_t perf_sleep_cycles = 0U;
	uint64_t perf_raster_cycles = 0U;
	uint64_t perf_video_cycles = 0U;
	uint64_t perf_usb_poll_cycles = 0U;
	uint64_t perf_guest_cycles = 0U;
	uint32_t perf_guest_max_cycles = 0U;
	uint32_t perf_guest_calls = 0U;
	uint32_t perf_video_calls = 0U;
	uint32_t perf_last_report_ms;
#endif
#if defined(CONFIG_MCX_MAC_UMAC_INSTR_COUNT)
	uint32_t instr_last_report_ms;
#endif
#if defined(CONFIG_MCX_MAC_UMAC_OPCODE_PROFILE) || defined(CONFIG_MCX_MAC_UMAC_CYCLE_PROFILE)
	uint32_t profile_next_report_ms;
#endif
	int ret;

#if defined(CONFIG_MCX_MAC_USB_IMAGE_TRANSFER)
	/* The two roles share USB1 and must never own it simultaneously. */
	if (umac_usb_transfer_requested()) {
		return umac_usb_transfer_run();
	}
#endif

	printk("mcx_mac: Phase 3 uMac %uK %s\n",
	       (unsigned int)(UMAC_GUEST_RAM_BYTES / 1024U),
	       IS_ENABLED(CONFIG_MCX_MAC_UMAC_MEDIA_FROM_SLOT1) ?
	       "separately installed media (image-1 slot)" :
	       IS_ENABLED(CONFIG_MCX_MAC_USB_MOUSE) ?
	       "private ROM + writable System disk, generic USB HID keyboard/mouse" :
	       IS_ENABLED(CONFIG_MCX_MAC_UMAC_BOOT) ?
	       "private ROM + read-only System disk, UART RX diagnostic EXP-41" :
	       "synthetic CPU EXP-34");

#if defined(CONFIG_MCX_MAC_UMAC_OPCODE_PROFILE)
	mcx_opcode_profile_init();
#elif defined(CONFIG_MCX_MAC_UMAC_CYCLE_PROFILE)
	mcx_cycle_profile_init();
#endif
#if defined(CONFIG_MCX_MAC_UMAC_OPCODE_PROFILE) || defined(CONFIG_MCX_MAC_UMAC_CYCLE_PROFILE)
	printk("DIAG CACHE LPCAC_CTRL=%08x enabled=%u NVM_CTRL=%08x\n",
	       (unsigned int)SYSCON->LPCAC_CTRL,
	       (SYSCON->LPCAC_CTRL & SYSCON_LPCAC_CTRL_DIS_LPCAC_MASK) == 0U,
	       (unsigned int)SYSCON->NVM_CTRL);
#endif

	if (IS_ENABLED(CONFIG_MCX_MAC_M68K_BUS_DIAG) &&
	    !m68k_bus_self_test()) {
		printk("M68K bus self-test failed; CPU integration disabled\n");
	}
	if (!umac_guest_ram_prepare()) {
		printk("DIAG uMac guest RAM=%u result=FAIL\n",
		       (unsigned int)umac_guest_ram_size());
		return -1;
	}
	printk("DIAG uMac guest RAM=%u result=PASS\n",
	       (unsigned int)umac_guest_ram_size());
#if defined(CONFIG_MCX_MAC_EXTERNAL_FLASH_PROBE)
	(void)umac_external_flash_probe();
#endif
#if defined(CONFIG_MCX_MAC_UMAC_SMOKE)
	printk("DIAG uMac synthetic CPU=%s (not Macintosh boot)\n",
	       umac_smoke_test() ? "PASS" : "FAIL");
#endif

#if defined(CONFIG_MCX_MAC_USB_MOUSE)
	ret = umac_usb_mouse_init();
	if (ret != 0) {
		printk("DIAG USB HID unavailable; continuing VGA/uMac\n");
	} else {
		/* Give enumeration an uncontended window before FlexIO/EDMA
		 * scanout starts; this differentiates startup timing from VGA load. */
		printk("DIAG USB pre-video enumeration window start\n");
		k_sleep(K_SECONDS(3));
		umac_usb_mouse_report();
		(void)umac_usb_hid_bind_interfaces();
		printk("DIAG USB pre-video enumeration window end\n");
	}
#endif

	ret = vga_init();
	if (ret != 0) {
		printk("VGA init failed: %d\n", ret);
		return ret;
	}

	ret = vga_start();
	if (ret != 0) {
		printk("VGA start failed: %d\n", ret);
		return ret;
	}
#if defined(CONFIG_MCX_MAC_UMAC_BOOT)
	guest_active = umac_boot_init();
	next_guest_ms = k_uptime_get_32();
	printk("DIAG uMac boot init=%s disk=volatile-writable\n",
	       guest_active ? "PASS" : "FAIL");
	if (guest_active) {
		umac_serial_input_init();
	}
#endif

	vga_get_timing_report(&report);
	printk("Nominal HSYNC: %u.%03u kHz, VSYNC: %u.%03u Hz\n",
	       report.hsync_millihz / 1000000U,
	       (report.hsync_millihz / 1000U) % 1000U,
	       report.vsync_millihz / 1000U,
	       report.vsync_millihz % 1000U);
	printk("Probe PIO0_8 (HSYNC) and PIO0_9 (VSYNC)\n");
	printk("Framebuffer: 512x342 mono, %u bytes; video path: %s\n",
	       (unsigned int)vga_framebuffer_size(),
	       IS_ENABLED(CONFIG_MCX_MAC_SMARTDMA_GUEST_DESCRIPTOR) ?
	       "SmartDMA direct guest pixels, Flash schedule (no raster buffer)" :
	       IS_ENABLED(CONFIG_MCX_MAC_SMARTDMA_DIRECT) ?
	       "experimental one-frame SmartDMA raster (no line IRQ)" :
	       IS_ENABLED(CONFIG_MCX_MAC_CONTINUOUS_RASTER) ?
	       "continuous cyclic EDMA raster (no line IRQ)" :
	       IS_ENABLED(CONFIG_MCX_MAC_HARDWARE_VIDEO_DIAG) ?
	       "FlexIO hardware timing diagnostic (CPU and DMA bypassed)" :
	       IS_ENABLED(CONFIG_MCX_MAC_SOLID_VIDEO_DIAG) ?
	       "CPU solid diagnostic (DMA bypassed)" :
	       vga_smartdma_is_ready() ?
	       "SmartDMA self-test + linked EDMA scanout" : "not ready");
	printk("VIDEO: PIO2_8 (J8-13); %s\n",
	       IS_ENABLED(CONFIG_MCX_MAC_ANIMATED_TEST) ?
	       "vblank-updated moving checkerboard" :
	       IS_ENABLED(CONFIG_MCX_MAC_SMARTDMA_GUEST_DESCRIPTOR) ?
	       "512x342 guest framebuffer, direct scanout" :
	       IS_ENABLED(CONFIG_MCX_MAC_SMARTDMA_DIRECT) ?
	       "512x342 normal framebuffer, vblank commit, one-frame ring" :
	       IS_ENABLED(CONFIG_MCX_MAC_CONTINUOUS_RASTER) ?
	       "512x342 normal framebuffer, vblank commit, dual-frame FIFO" :
	       IS_ENABLED(CONFIG_MCX_MAC_HARDWARE_VIDEO_DIAG) ?
	       "hardware-timed horizontal window, no line IRQ" :
	       IS_ENABLED(CONFIG_MCX_MAC_SOLID_VIDEO_DIAG) ?
	       "solid rectangle, no framebuffer DMA" :
	       vga_smartdma_scanout_enabled() ?
	       "512x342 centered, static 32-pixel checkerboard" :
	       "disabled after diagnostic failure (sync only)");

	next_report_ms = k_uptime_get_32() + 5000U;
#if defined(CONFIG_MCX_MAC_UMAC_PERF_DIAG)
	perf_last_report_ms = k_uptime_get_32();
#endif
#if defined(CONFIG_MCX_MAC_UMAC_INSTR_COUNT)
	instr_last_report_ms = k_uptime_get_32();
#endif
#if defined(CONFIG_MCX_MAC_UMAC_OPCODE_PROFILE) || defined(CONFIG_MCX_MAC_UMAC_CYCLE_PROFILE)
	profile_next_report_ms = k_uptime_get_32() + 30000U;
#endif
	for (;;) {
		uint32_t now;
		struct umac_timing_events events;
#if defined(CONFIG_MCX_MAC_UMAC_PERF_DIAG)
		uint32_t perf_start = k_cycle_get_32();
#endif

#if defined(CONFIG_MCX_MAC_UMAC_YIELD_SCHED)
		if (guest_active) {
			k_yield();
		} else {
			k_sleep(K_MSEC(1));
		}
#elif defined(CONFIG_MCX_MAC_UMAC_FAST_SCHED)
		k_sleep(guest_active ? K_USEC(100) : K_MSEC(1));
#else
		k_sleep(K_MSEC(1));
#endif
#if defined(CONFIG_MCX_MAC_UMAC_PERF_DIAG)
		perf_sleep_cycles += k_cycle_get_32() - perf_start;
		perf_start = k_cycle_get_32();
#endif
		vga_smartdma_service();
#if defined(CONFIG_MCX_MAC_UMAC_PERF_DIAG)
		perf_raster_cycles += k_cycle_get_32() - perf_start;
#endif
		now = k_uptime_get_32();
		events = umac_timing_poll(&timing, vga_flexio_get_frame_count(), now);
		umac_vsync_ticks += events.vsync ? 1U : 0U;
		umac_second_ticks += events.second ? 1U : 0U;
#if defined(CONFIG_MCX_MAC_UMAC_BOOT)
		if (guest_active) {
			umac_serial_input_poll();
#if defined(CONFIG_MCX_MAC_USB_MOUSE)
#if defined(CONFIG_MCX_MAC_UMAC_PERF_DIAG)
			perf_start = k_cycle_get_32();
#endif
			umac_usb_mouse_poll();
#if defined(CONFIG_MCX_MAC_UMAC_PERF_DIAG)
			perf_usb_poll_cycles += k_cycle_get_32() - perf_start;
#endif
#endif
			if (!umac_serial_guest_paused() && events.vsync) {
				umac_vsync_event();
				if (!umac_serial_test_pattern_enabled()) {
#if defined(CONFIG_MCX_MAC_UMAC_PERF_DIAG)
					perf_start = k_cycle_get_32();
#endif
					ret = umac_video_present(umac_guest_ram_get(),
						 umac_guest_ram_size(),
						 umac_get_fb_offset());
#if defined(CONFIG_MCX_MAC_UMAC_PERF_DIAG)
					perf_video_cycles += k_cycle_get_32() - perf_start;
					perf_video_calls++;
#endif
					if (ret != 0) {
						printk("DIAG uMac video present failed: %d\n", ret);
						guest_active = false;
					}
				}
			}
			if (!umac_serial_guest_paused() && events.second) {
				umac_1hz_event();
			}
			if (guest_active && !umac_serial_guest_paused() &&
			    (int32_t)(now - next_guest_ms) >= 0) {
#if defined(CONFIG_MCX_MAC_UMAC_PERF_DIAG)
				perf_start = k_cycle_get_32();
#endif
				ret = umac_loop();
#if defined(CONFIG_MCX_MAC_UMAC_PERF_DIAG)
				uint32_t elapsed = k_cycle_get_32() - perf_start;

				perf_guest_cycles += elapsed;
				perf_guest_calls++;
				if (elapsed > perf_guest_max_cycles) {
					perf_guest_max_cycles = elapsed;
				}
#endif
				if (ret != 0) {
					printk("DIAG uMac guest stopped\n");
					guest_active = false;
				} else {
					guest_loops++;
					next_guest_ms += MCX_MAC_GUEST_LOOP_MS;
					if ((int32_t)(now - next_guest_ms) > 20) {
						next_guest_ms = now + MCX_MAC_GUEST_LOOP_MS;
					}
				}
			}
		}
#endif
	if ((int32_t)(now - next_report_ms) < 0) {
		continue;
	}
	next_report_ms += 5000U;
#if defined(CONFIG_MCX_MAC_UMAC_OPCODE_PROFILE) || defined(CONFIG_MCX_MAC_UMAC_CYCLE_PROFILE)
	if ((int32_t)(now - profile_next_report_ms) >= 0) {
		profile_next_report_ms += 30000U;
#if defined(CONFIG_MCX_MAC_UMAC_OPCODE_PROFILE)
		mcx_opcode_profile_report();
#else
		mcx_cycle_profile_report();
#endif
	}
#endif
#if defined(CONFIG_MCX_MAC_UMAC_INSTR_COUNT)
	{
		uint32_t interval_ms = now - instr_last_report_ms;
		uint32_t instructions = mcx_mac_guest_instructions;

		mcx_mac_guest_instructions = 0U;
		instr_last_report_ms = now;
		/* instructions/ms has the same numeric value as kIPS. */
		printk("DIAG M68K interval_ms=%u instructions=%u kips=%u\n",
		       interval_ms, instructions,
		       interval_ms == 0U ? 0U : instructions / interval_ms);
	}
#endif
#if defined(CONFIG_MCX_MAC_USB_THREAD_PROFILE)
	report_usb_thread_cycles(5000U);
#endif
#if defined(CONFIG_MCX_MAC_UMAC_PERF_DIAG)
		const uint32_t cycles_per_ms = sys_clock_hw_cycles_per_sec() / 1000U;
		uint32_t guest_avg_us = perf_guest_calls == 0U ? 0U :
			(uint32_t)((perf_guest_cycles / perf_guest_calls) /
				     (cycles_per_ms / 1000U));

		printk("DIAG PERF interval_ms=%u guest_calls=%u guest_ms=%u "
		       "guest_avg/max_us=%u/%u video_calls=%u video_ms=%u "
		       "raster_ms=%u usb_poll_ms=%u sleep_ms=%u\n",
		       now - perf_last_report_ms, perf_guest_calls,
		       (uint32_t)(perf_guest_cycles / cycles_per_ms),
		       guest_avg_us,
		       perf_guest_max_cycles / (cycles_per_ms / 1000U),
		       perf_video_calls,
		       (uint32_t)(perf_video_cycles / cycles_per_ms),
		       (uint32_t)(perf_raster_cycles / cycles_per_ms),
		       (uint32_t)(perf_usb_poll_cycles / cycles_per_ms),
		       (uint32_t)(perf_sleep_cycles / cycles_per_ms));
		perf_last_report_ms = now;
		perf_sleep_cycles = 0U;
		perf_raster_cycles = 0U;
		perf_video_cycles = 0U;
		perf_usb_poll_cycles = 0U;
		perf_guest_cycles = 0U;
		perf_guest_max_cycles = 0U;
		perf_guest_calls = 0U;
		perf_video_calls = 0U;
#endif
		vga_smartdma_get_stats(&stats);
		vga_smartdma_linked_diag();
		vga_smartdma_phase_report();
		printk("DIAG RASTER freeze=%u shifter_errors=%08x\n",
		       vga_raster_is_frozen() ? 1U : 0U,
		       vga_flexio_take_shift_errors());
		printk("EDMA lines: %u start, %u complete, %u dropped, "
		       "%u errors, %u timeouts; sync frames: %u, recovered: %u, "
		       "raster commits: %u; "
		       "transfer us last/max: %u/%u\n",
		       stats.started_lines, stats.completed_lines,
		       stats.dropped_lines, stats.start_errors, stats.timeouts,
		       stats.sync_frames, stats.recovered_lines,
		       stats.raster_commits,
		       (uint32_t)(((uint64_t)stats.transfer_last_cycles * 1000000U) /
				  sys_clock_hw_cycles_per_sec()),
			(uint32_t)(((uint64_t)stats.transfer_max_cycles * 1000000U) /
				  sys_clock_hw_cycles_per_sec()));
#if defined(CONFIG_MCX_MAC_UMAC_BOOT)
	struct umac_mouse_diagnostics mouse_diag;

#if defined(CONFIG_MCX_MAC_UMAC_VIDEO_DIRTY_TRACK)
		struct umac_video_dirty_stats video_dirty;

		umac_video_get_dirty_stats(&video_dirty);
		printk("DIAG uMac video compared=%u skipped=%u changed=%u guest_writes=%u "
		       "periodic_checks=%u untracked_changes=%u\n",
		       video_dirty.compared, video_dirty.skipped,
		       video_dirty.changed, video_dirty.guest_writes,
		       video_dirty.periodic_checks, video_dirty.untracked_changes);
#endif

		umac_serial_input_report();
		umac_mouse_get_diagnostics(&mouse_diag);
		printk("DIAG uMac mouse input=%u,%u clipped=%u,%u steps=%u,%u "
		       "limit=%u irq_busy=%u pending=%d,%d\n",
		       mouse_diag.input_x, mouse_diag.input_y,
		       mouse_diag.clipped_x, mouse_diag.clipped_y,
		       mouse_diag.steps_x, mouse_diag.steps_y,
		       mouse_diag.limit_events, mouse_diag.irq_busy,
		       mouse_diag.pending_x, mouse_diag.pending_y);
		printk("DIAG uMac disk COW sectors=%u/%u writes=%u errors=%u (volatile)\n",
		       umac_disk_overlay_used(), UMAC_DISK_OVERLAY_SECTORS,
		       umac_disk_overlay_write_count(),
		       umac_disk_overlay_error_count());
#if defined(CONFIG_MCX_MAC_USB_MOUSE)
		umac_usb_mouse_report();
#endif
		printk("DIAG uMac clock vsync=%u second=%u guest=%s loops=%u pc=%06x\n",
		       umac_vsync_ticks, umac_second_ticks,
		       guest_active ? "active" : "inactive", guest_loops,
		       guest_active ? m68k_get_reg(NULL, M68K_REG_PC) : 0U);
#else
		printk("DIAG uMac clock vsync=%u second=%u guest=inactive\n",
		       umac_vsync_ticks, umac_second_ticks);
#endif
	}
}
```
